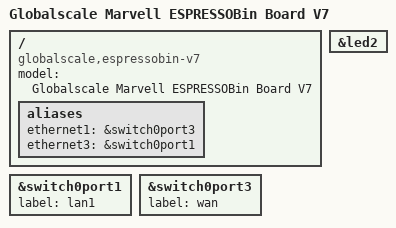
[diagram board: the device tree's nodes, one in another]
// SPDX-License-Identifier: (GPL-2.0+ OR MIT)
/*
 * Device Tree file for Globalscale Marvell ESPRESSOBin Board V7
 * Copyright (C) 2018 Marvell
 *
 * Romain Perier <romain.perier@free-electrons.com>
 * Konstantin Porotchkin <kostap@marvell.com>
 *
 */
/*
 * Schematic available at http://espressobin.net/wp-content/uploads/2020/05/ESPRESSObin_V7-0_Schematic.pdf
 */

/dts-v1/;

#include "armada-3720-espressobin.dtsi"

/ {
	model = "Globalscale Marvell ESPRESSOBin Board V7";
	compatible = "globalscale,espressobin-v7", "globalscale,espressobin",
		     "marvell,armada3720", "marvell,armada3710";

	aliases {
		/* ethernet1 is wan port */
		ethernet1 = &switch0port3;
		ethernet3 = &switch0port1;
	};
};

&switch0port1 {
	label = "lan1";
};

&switch0port3 {
	label = "wan";
};

&led2 {
	status = "okay";
};
